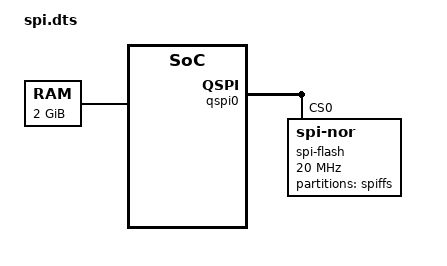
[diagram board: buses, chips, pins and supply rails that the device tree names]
/dts-v1/;
/ {
    chosen {
        bootargs = "console=ttyS0";
    };

    aliases {
        spi0 = &qspi0;
    };

    memory {
        device_type = "memory";
        reg = <0x0 0x80000000>;
    };

    qspi0: qspi@10020000 {
        compatible = "sifive,qspi0";
        reg = <0x0 0x10020000 0x0 0x10000>;
        status = "okay";
        #address-cells = <1>;
        #size-cells = <1>;
        spi-flash@0 {
            compatible = "jedec,spi-nor";
            reg = <0x0 0x0 0x0 0x800000>; // 8MB
            spi-max-frequency = <20000000>;
            m25p,fast-read;
            partition@0 {
                label = "spiffs";
                reg = <0x0 0x0 0x0 0x400000>; // 4MB
            };
        };
    };
};

